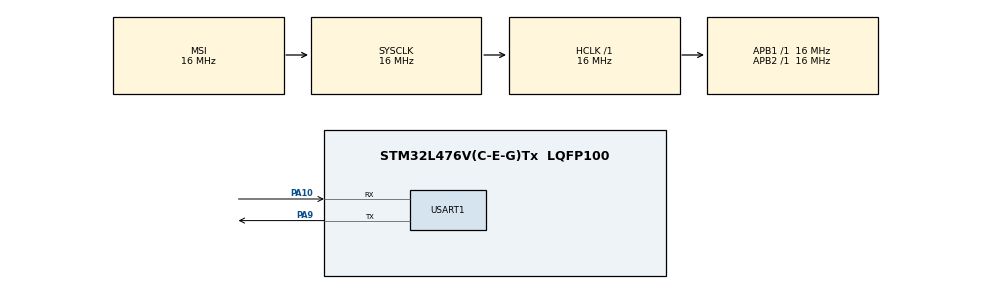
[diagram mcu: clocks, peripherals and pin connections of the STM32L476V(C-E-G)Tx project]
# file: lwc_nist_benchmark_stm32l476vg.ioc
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Mcu.Family=STM32L4
RCC.MSI_VALUE=16000000
PA14\ (JTCK-SWCLK).Mode=Serial_Wire
RCC.CortexFreq_Value=16000000
PA10.Mode=Asynchronous
NVIC.TIM6_DAC_IRQn=true\:0\:0\:false\:false\:true\:true\:true
VP_TIM6_VS_ClockSourceINT.Mode=Enable_Timer
ProjectManager.StackSize=0x400
PA14\ (JTCK-SWCLK).Signal=SYS_JTCK-SWCLK
USART1.VirtualMode-Asynchronous=VM_ASYNC
PA9.Mode=Asynchronous
ProjectManager.TargetToolchain=STM32CubeIDE
RCC.HCLKFreq_Value=16000000
RCC.APB2TimFreq_Value=16000000
PA9.Signal=USART1_TX
RCC.USBFreq_Value=64000000
RCC.LSE_VALUE=32768
RCC.AHBFreq_Value=16000000
RCC.HSE_VALUE=8000000
board=custom
RCC.VCOOutputFreq_Value=128000000
RCC.APB2Freq_Value=16000000
RCC.ADCFreq_Value=64000000
Mcu.Name=STM32L476V(C-E-G)Tx
PA13\ (JTMS-SWDIO).Mode=Serial_Wire
RCC.SYSCLKFreq_VALUE=16000000
Mcu.Package=LQFP100
PA10.Signal=USART1_RX
ProjectManager.HeapSize=0x200
RCC.HSI_VALUE=16000000
NVIC.PriorityGroup=NVIC_PRIORITYGROUP_4
RCC.APB1TimFreq_Value=16000000
PA13\ (JTMS-SWDIO).Signal=SYS_JTMS-SWDIO
RCC.APB1Freq_Value=16000000
RCC.MSIClockRange=RCC_MSIRANGE_8

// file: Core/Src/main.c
/* USER CODE BEGIN Header */
/**
  ******************************************************************************
  * @file           : main.c
  * @brief          : Main program body
  ******************************************************************************
  * @attention
  *
  * <h2><center>&copy; Copyright (c) 2021 STMicroelectronics.
  * All rights reserved.</center></h2>
  *
  * This software component is licensed by ST under BSD 3-Clause license,
  * the "License"; You may not use this file except in compliance with the
  * License. You may obtain a copy of the License at:
  *                        opensource.org/licenses/BSD-3-Clause
  *
  ******************************************************************************
  */
/* USER CODE END Header */
#include "main.h"

/* USER CODE BEGIN Includes */
#include "lwc_config.h"
/* USER CODE END Includes */

TIM_HandleTypeDef htim6;

UART_HandleTypeDef huart1;

void SystemClock_Config(void);
static void MX_GPIO_Init(void);
static void MX_TIM6_Init(void);
static void MX_USART1_UART_Init(void);

/* USER CODE BEGIN 0 */
int genkat_benchmark_hash_aead(void);
/* USER CODE END 0 */

int main(void)
{

  /* MCU Configuration--------------------------------------------------------*/

  /* Reset of all peripherals, Initializes the Flash interface and the Systick. */
  HAL_Init();

  /* Configure the system clock */
  SystemClock_Config();

  /* Initialize all configured peripherals */
  MX_GPIO_Init();
  MX_TIM6_Init();
  MX_USART1_UART_Init();

  /* Infinite loop */
  /* USER CODE BEGIN WHILE */
  while (1)
  {
	  genkat_benchmark_hash_aead();
	  HAL_Delay(1000000);
    /* USER CODE END WHILE */

  }
}

void SystemClock_Config(void)
{
  RCC_OscInitTypeDef RCC_OscInitStruct = {0};
  RCC_ClkInitTypeDef RCC_ClkInitStruct = {0};
  RCC_PeriphCLKInitTypeDef PeriphClkInit = {0};

  /** Initializes the RCC Oscillators according to the specified parameters
  * in the RCC_OscInitTypeDef structure.
  */
  RCC_OscInitStruct.OscillatorType = RCC_OSCILLATORTYPE_MSI;
  RCC_OscInitStruct.MSIState = RCC_MSI_ON;
  RCC_OscInitStruct.MSICalibrationValue = 0;
  RCC_OscInitStruct.MSIClockRange = RCC_MSIRANGE_8;
  RCC_OscInitStruct.PLL.PLLState = RCC_PLL_NONE;
  if (HAL_RCC_OscConfig(&RCC_OscInitStruct) != HAL_OK)
  {
    Error_Handler();
  }
  /** Initializes the CPU, AHB and APB buses clocks
  */
  RCC_ClkInitStruct.ClockType = RCC_CLOCKTYPE_HCLK|RCC_CLOCKTYPE_SYSCLK
                              |RCC_CLOCKTYPE_PCLK1|RCC_CLOCKTYPE_PCLK2;
  RCC_ClkInitStruct.SYSCLKSource = RCC_SYSCLKSOURCE_MSI;
  RCC_ClkInitStruct.AHBCLKDivider = RCC_SYSCLK_DIV1;
  RCC_ClkInitStruct.APB1CLKDivider = RCC_HCLK_DIV1;
  RCC_ClkInitStruct.APB2CLKDivider = RCC_HCLK_DIV1;

  if (HAL_RCC_ClockConfig(&RCC_ClkInitStruct, FLASH_LATENCY_0) != HAL_OK)
  {
    Error_Handler();
  }
  PeriphClkInit.PeriphClockSelection = RCC_PERIPHCLK_USART1;
  PeriphClkInit.Usart1ClockSelection = RCC_USART1CLKSOURCE_PCLK2;
  if (HAL_RCCEx_PeriphCLKConfig(&PeriphClkInit) != HAL_OK)
  {
    Error_Handler();
  }
  /** Configure the main internal regulator output voltage
  */
  if (HAL_PWREx_ControlVoltageScaling(PWR_REGULATOR_VOLTAGE_SCALE1) != HAL_OK)
  {
    Error_Handler();
  }
}

static void MX_TIM6_Init(void)
{

  TIM_MasterConfigTypeDef sMasterConfig = {0};

  htim6.Instance = TIM6;
  htim6.Init.Prescaler = 0;
  htim6.Init.CounterMode = TIM_COUNTERMODE_UP;
  htim6.Init.Period = 65535;
  htim6.Init.AutoReloadPreload = TIM_AUTORELOAD_PRELOAD_DISABLE;
  if (HAL_TIM_Base_Init(&htim6) != HAL_OK)
  {
    Error_Handler();
  }
  sMasterConfig.MasterOutputTrigger = TIM_TRGO_RESET;
  sMasterConfig.MasterSlaveMode = TIM_MASTERSLAVEMODE_DISABLE;
  if (HAL_TIMEx_MasterConfigSynchronization(&htim6, &sMasterConfig) != HAL_OK)
  {
    Error_Handler();
  }

}

static void MX_USART1_UART_Init(void)
{

  huart1.Instance = USART1;
  huart1.Init.BaudRate = 115200;
  huart1.Init.WordLength = UART_WORDLENGTH_8B;
  huart1.Init.StopBits = UART_STOPBITS_1;
  huart1.Init.Parity = UART_PARITY_NONE;
  huart1.Init.Mode = UART_MODE_TX_RX;
  huart1.Init.HwFlowCtl = UART_HWCONTROL_NONE;
  huart1.Init.OverSampling = UART_OVERSAMPLING_16;
  huart1.Init.OneBitSampling = UART_ONE_BIT_SAMPLE_DISABLE;
  huart1.AdvancedInit.AdvFeatureInit = UART_ADVFEATURE_NO_INIT;
  if (HAL_UART_Init(&huart1) != HAL_OK)
  {
    Error_Handler();
  }

}

static void MX_GPIO_Init(void)
{

  /* GPIO Ports Clock Enable */
  LL_AHB2_GRP1_EnableClock(LL_AHB2_GRP1_PERIPH_GPIOA);

}

void Error_Handler(void)
{
  __disable_irq();
  while (1)
  {
  }
}

/************************ (C) COPYRIGHT STMicroelectronics *****END OF FILE****/
